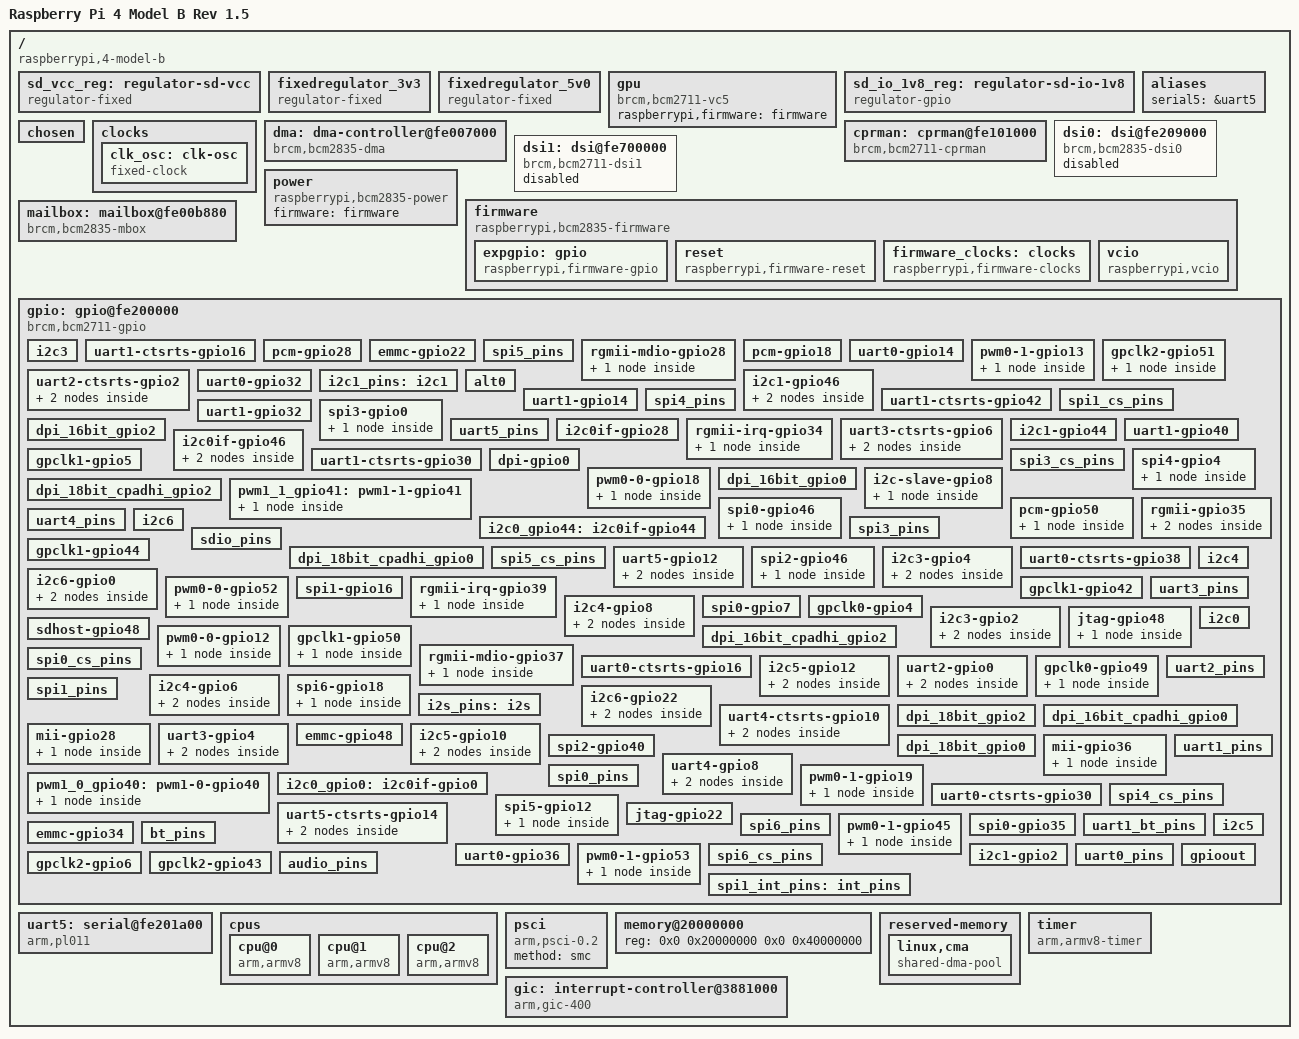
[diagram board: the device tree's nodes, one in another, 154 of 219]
/dts-v1/;
// TODO: Fix 
//
//buildroot login: [   15.462113] platform regulator-sd-vcc: deferred probe pending: platform: supplier firmware:gpio not ready
//[   15.471840] platform firmware:gpio: deferred probe pending: (reason unknown)
//[   15.478986] platform regulator-sd-io-1v8: deferred probe pending: platform: supplier firmware:gpio not ready
//[   15.488930] platform firmware:clocks: deferred probe pending: (reason unknown)
//[   15.496244] platform firmware:reset: deferred probe pending: (reason unknown)
/ {
	#address-cells = <2>;
	#size-cells = <2>;
  interrupt-parent = <&gic>;
	model = "Raspberry Pi 4 Model B Rev 1.5";
	serial-number = "100000000a471c8d";
	compatible = "raspberrypi,4-model-b\0brcm,bcm2711";


	sd_vcc_reg: regulator-sd-vcc {
		regulator-max-microvolt = <0x325aa0>;
		regulator-boot-on;
		gpio = <&expgpio 0x06 0x00>;
		enable-active-high;
		regulator-min-microvolt = <0x325aa0>;
		regulator-name = "vcc-sd";
		compatible = "regulator-fixed";
	};

	fixedregulator_3v3 {
		regulator-max-microvolt = <0x325aa0>;
		regulator-always-on;
		regulator-min-microvolt = <0x325aa0>;
		regulator-name = "3v3";
		compatible = "regulator-fixed";
	};

	fixedregulator_5v0 {
		regulator-max-microvolt = <0x4c4b40>;
		regulator-always-on;
		regulator-min-microvolt = <0x4c4b40>;
		regulator-name = "5v0";
		compatible = "regulator-fixed";
	};

	gpu {
		compatible = "brcm,bcm2711-vc5";
		status = "okay";
		raspberrypi,firmware = <&firmware>;
	};

	sd_io_1v8_reg: regulator-sd-io-1v8 {
		regulator-max-microvolt = <0x325aa0>;
		regulator-boot-on;
		regulator-settling-time-us = <0x1388>;
		regulator-always-on;
		regulator-min-microvolt = <0x1b7740>;
		regulator-name = "vdd-sd-io";
		compatible = "regulator-gpio";
		status = "okay";
		states = <0x1b7740 0x01 0x325aa0 0x00>;
		gpios = <&expgpio 0x04 0x00>;
	};

	aliases {
		serial5 = &uart5;
	//	ethernet0 = &genet;
	};

	chosen {
		stdout-path = "serial5:115200n8";
		bootargs = "coherent_pool=1M earlycon console=serial5,115200 isolcpus=2";
		//bootargs = "coherent_pool=1M earlycon console=serial5,115200 clk_ignore_unused ip=192.168.42.15 carrier_timeout=0 isolcpus=2";
	};


// zone_dma {
// 	dma-ranges = <0x00 0x00 0x00 0x40000000>;
// 	#address-cells = <0x01>;
// 	#size-cells = <0x01>;
// };

	clocks {

	clk_osc:	clk-osc {
			clock-output-names = "osc";
			#clock-cells = <0x00>;
			clock-frequency = <0x337f980>;
			compatible = "fixed-clock";
		};
    };

// soc:	soc {
//		compatible = "simple-bus";
//		#address-cells = <0x01>;
//		#size-cells = <0x01>;
//		ranges = <0x7e000000 0x00 0xfe000000 0x1800000 
//                  0x7c000000 0x00 0xfc000000 0x2000000 
//                  0x40000000 0x00 0xff800000 0x800000>;
//		dma-ranges = <0xc0000000 0x00 0x00 0x40000000 
//                      0x7c000000 0x00 0xfc000000 0x3800000>;
//
//
	 dma:	dma-controller@fe007000 {
			interrupts = <0x00 0x50 0x04 0x00 0x51 0x04 0x00 0x52 0x04 0x00 0x53 0x04 0x00 0x54 0x04 0x00 0x55 0x04 0x00 0x56 0x04 0x00 0x57 0x04 0x00 0x57 0x04 0x00 0x58 0x04 0x00 0x58 0x04>;
			brcm,dma-channel-mask = <0x7f5>;
			compatible = "brcm,bcm2835-dma";
			interrupt-names = "dma0\0dma1\0dma2\0dma3\0dma4\0dma5\0dma6\0dma7\0dma8\0dma9\0dma10";
			reg = <0x0 0xfe007000 0x0 0xb00>;
			#dma-cells = <0x01>;
		};
// };

//
//

	cprman:	cprman@fe101000 {
			clocks = <&clk_osc &dsi0 0x00 &dsi0 0x01 &dsi0 0x02 &dsi1 0x00 &dsi1 0x01 &dsi1 0x02>;
//			clocks = <&clk_osc>;
			#clock-cells = <0x01>;
			compatible = "brcm,bcm2711-cprman";
			firmware = <&firmware>;
			reg = <0x0 0xfe101000 0x0 0x2000>;
		};

	dsi0:	dsi@fe209000 {
			power-domains = <&power 0x11>;
			#address-cells = <0x01>;
			clock-output-names = "dsi0_byte\0dsi0_ddr2\0dsi0_ddr";
			clock-names = "phy\0escape\0pixel";
			interrupts = <0x00 0x64 0x04>;
			clocks = <&cprman 0x22 &cprman 0x2f &cprman 0x31>;
			#size-cells = <0x00>;
			#clock-cells = <0x01>;
			compatible = "brcm,bcm2835-dsi0";
			status = "disabled";
			reg = <0x0 0xfe209000 0x0 0x78>;
		};

	dsi1:	dsi@fe700000 {
			power-domains = <&power 0x12>;
			#address-cells = <0x01>;
			clock-output-names = "dsi1_byte\0dsi1_ddr2\0dsi1_ddr";
			clock-names = "phy\0escape\0pixel";
			interrupts = <0x00 0x6c 0x04>;
			clocks = <&cprman 0x23 &cprman 0x30 &cprman 0x32>;
			#size-cells = <0x00>;
			#clock-cells = <0x01>;
			compatible = "brcm,bcm2711-dsi1";
			status = "disabled";
			reg = <0x0 0xfe700000 0x0 0x8c>;
		};

	power: power {
			compatible = "raspberrypi,bcm2835-power";
			firmware = <&firmware>;
			#power-domain-cells = <0x01>;
		};

	firmware:	firmware {
			dma-ranges;
			#address-cells = <0x01>;
			#size-cells = <0x01>;
			compatible = "raspberrypi,bcm2835-firmware\0simple-mfd";
			mboxes = <&mailbox>;

		expgpio:	gpio {
				gpio-controller;
				gpio-line-names = "BT_ON\0WL_ON\0PWR_LED_OFF\0GLOBAL_RESET\0VDD_SD_IO_SEL\0CAM_GPIO\0SD_PWR_ON\0SD_OC_N";
				compatible = "raspberrypi,firmware-gpio";
				status = "okay";
				#gpio-cells = <0x02>;
			};

		reset:	reset {
				#reset-cells = <0x01>;
				compatible = "raspberrypi,firmware-reset";
			};

		firmware_clocks:	clocks {
				#clock-cells = <0x01>;
				compatible = "raspberrypi,firmware-clocks";
			};

		vcio:	vcio {
				compatible = "raspberrypi,vcio";
			};
		};

	mailbox:	mailbox@fe00b880 {
			interrupts = <0x00 0x21 0x04>;
			#mbox-cells = <0x00>;
			compatible = "brcm,bcm2835-mbox";
			reg = <0x0 0xfe00b880 0x0 0x40>;
		};


	gpio:	gpio@fe200000 {
			compatible = "brcm,bcm2711-gpio";
			reg = <0x0 0xfe200000 0x0 0xb4>;
			interrupts = <0x00 0x71 0x04 0x00 0x72 0x04>;
			gpio-controller;
			#gpio-cells = <0x02>;
			interrupt-controller;
			#interrupt-cells = <0x02>;
			gpio-ranges = <0x07 0x00 0x00 0x3a>;
			gpio-line-names = "ID_SDA\0ID_SCL\0GPIO2\0GPIO3\0GPIO4\0GPIO5\0GPIO6\0GPIO7\0GPIO8\0GPIO9\0GPIO10\0GPIO11\0GPIO12\0GPIO13\0GPIO14\0GPIO15\0GPIO16\0GPIO17\0GPIO18\0GPIO19\0GPIO20\0GPIO21\0GPIO22\0GPIO23\0GPIO24\0GPIO25\0GPIO26\0GPIO27\0RGMII_MDIO\0RGMIO_MDC\0CTS0\0RTS0\0TXD0\0RXD0\0SD1_CLK\0SD1_CMD\0SD1_DATA0\0SD1_DATA1\0SD1_DATA2\0SD1_DATA3\0PWM0_MISO\0PWM1_MOSI\0STATUS_LED_G_CLK\0SPIFLASH_CE_N\0SDA0\0SCL0\0RGMII_RXCLK\0RGMII_RXCTL\0RGMII_RXD0\0RGMII_RXD1\0RGMII_RXD2\0RGMII_RXD3\0RGMII_TXCLK\0RGMII_TXCTL\0RGMII_TXD0\0RGMII_TXD1\0RGMII_TXD2\0RGMII_TXD3";
			phandle = <0x07>;

			i2c3 {
				brcm,pull = <0x02>;
				brcm,function = <0x02>;
				phandle = <0x24>;
				brcm,pins = <0x04 0x05>;
			};

			uart1-ctsrts-gpio16 {
				brcm,function = <0x02>;
				phandle = <0x7f>;
				brcm,pins = <0x10 0x11>;
			};

			pcm-gpio28 {
				brcm,function = <0x06>;
				phandle = <0x72>;
				brcm,pins = <0x1c 0x1d 0x1e 0x1f>;
			};

			emmc-gpio22 {
				brcm,function = <0x07>;
				phandle = <0x65>;
				brcm,pins = <0x16 0x17 0x18 0x19 0x1a 0x1b>;
			};

			spi5_pins {
				brcm,function = <0x07>;
				phandle = <0x20>;
				brcm,pins = <0x0d 0x0e 0x0f>;
			};

			rgmii-mdio-gpio28 {
				phandle = <0xa0>;

				pins-mdio {
					function = "alt5";
					pins = "gpio28\0gpio29";
				};
			};

			pcm-gpio18 {
				brcm,function = <0x04>;
				phandle = <0x71>;
				brcm,pins = <0x12 0x13 0x14 0x15>;
			};

			uart0-gpio14 {
				brcm,function = <0x04>;
				phandle = <0x78>;
				brcm,pins = <0x0e 0x0f>;
			};

			pwm0-1-gpio13 {
				phandle = <0x98>;

				pin-pwm {
					function = "alt0";
					pins = "gpio13";
					bias-disable;
				};
			};

			gpclk2-gpio51 {
				phandle = <0x86>;

				pin-gpclk {
					function = "alt1";
					pins = "gpio51";
					bias-disable;
				};
			};

			uart2-ctsrts-gpio2 {
				phandle = <0xa9>;

				pin-cts {
					function = "alt4";
					pins = "gpio2";
					bias-pull-up;
				};

				pin-rts {
					function = "alt4";
					pins = "gpio3";
					bias-disable;
				};
			};

			uart0-gpio32 {
				brcm,pull = <0x00 0x02>;
				brcm,function = <0x07>;
				phandle = <0x7b>;
				brcm,pins = <0x20 0x21>;
			};

		i2c1_pins:	i2c1 {
				brcm,pull = <0x02>;
				brcm,function = <0x04>;
				phandle = <0x15>;
				brcm,pins = <0x02 0x03>;
			};

			alt0 {
				brcm,function = <0x04>;
				phandle = <0xb9>;
				brcm,pins = <0x04 0x05 0x07 0x08 0x09 0x0a 0x0b>;
			};

			i2c1-gpio46 {
				phandle = <0x88>;

				pin-scl {
					function = "alt1";
					pins = "gpio47";
					bias-disable;
				};

				pin-sda {
					function = "alt1";
					pins = "gpio46";
					bias-pull-up;
				};
			};

			uart1-gpio14 {
				brcm,function = <0x02>;
				phandle = <0x7e>;
				brcm,pins = <0x0e 0x0f>;
			};

			uart1-ctsrts-gpio42 {
				brcm,function = <0x02>;
				phandle = <0x83>;
				brcm,pins = <0x2a 0x2b>;
			};

		spi1_cs_pins:	spi1_cs_pins {
				brcm,function = <0x01>;
				phandle = <0xfe>;
				brcm,pins = <0x12>;
			};

			uart1-gpio32 {
				brcm,function = <0x02>;
				phandle = <0x80>;
				brcm,pins = <0x20 0x21>;
			};

			spi3-gpio0 {
				phandle = <0xa4>;

				pins-spi {
					function = "alt3";
					pins = "gpio0\0gpio1\0gpio2\0gpio3";
				};
			};

			dpi_16bit_gpio2 {
				brcm,function = <0x06>;
				phandle = <0xb5>;
				brcm,pins = <0x02 0x03 0x04 0x05 0x06 0x07 0x08 0x09 0x0a 0x0b 0x0c 0x0d 0x0e 0x0f 0x10 0x11 0x12 0x13>;
			};

		uart5_pins:	uart5_pins {
				brcm,pull = <0x00 0x02>;
				brcm,function = <0x03>;
				phandle = <0x1b>;
				brcm,pins = <0x0c 0x0d>;
			};

			spi4_pins {
				brcm,function = <0x07>;
				phandle = <0x1e>;
				brcm,pins = <0x05 0x06 0x07>;
			};

			i2c0if-gpio28 {
				brcm,function = <0x04>;
				phandle = <0x6d>;
				brcm,pins = <0x1c 0x1d>;
			};

			rgmii-irq-gpio34 {
				phandle = <0x9e>;

				pin-irq {
					function = "alt5";
					pins = "gpio34";
				};
			};

			uart3-ctsrts-gpio6 {
				phandle = <0xab>;

				pin-cts {
					function = "alt4";
					pins = "gpio6";
					bias-pull-up;
				};

				pin-rts {
					function = "alt4";
					pins = "gpio7";
					bias-disable;
				};
			};

			i2c1-gpio44 {
				brcm,function = <0x06>;
				phandle = <0x6f>;
				brcm,pins = <0x2c 0x2d>;
			};

			uart1-gpio40 {
				brcm,function = <0x02>;
				phandle = <0x82>;
				brcm,pins = <0x28 0x29>;
			};

			i2c0if-gpio46 {
				phandle = <0x87>;

				pin-scl {
					function = "alt0";
					pins = "gpio47";
					bias-disable;
				};

				pin-sda {
					function = "alt0";
					pins = "gpio46";
					bias-pull-up;
				};
			};

			gpclk1-gpio5 {
				brcm,function = <0x04>;
				phandle = <0x68>;
				brcm,pins = <0x05>;
			};

			uart1-ctsrts-gpio30 {
				brcm,function = <0x02>;
				phandle = <0x81>;
				brcm,pins = <0x1e 0x1f>;
			};

			dpi-gpio0 {
				brcm,function = <0x06>;
				phandle = <0x64>;
				brcm,pins = <0x00 0x01 0x02 0x03 0x04 0x05 0x06 0x07 0x08 0x09 0x0a 0x0b 0x0c 0x0d 0x0e 0x0f 0x10 0x11 0x12 0x13 0x14 0x15 0x16 0x17 0x18 0x19 0x1a 0x1b>;
			};

		spi3_cs_pins:	spi3_cs_pins {
				brcm,function = <0x01>;
				phandle = <0x1d>;
				brcm,pins = <0x00 0x18>;
			};

			spi4-gpio4 {
				phandle = <0xa5>;

				pins-spi {
					function = "alt3";
					pins = "gpio4\0gpio5\0gpio6\0gpio7";
				};
			};

			pwm0-0-gpio18 {
				phandle = <0x97>;

				pin-pwm {
					function = "alt5";
					pins = "gpio18";
					bias-disable;
				};
			};

			dpi_16bit_gpio0 {
				brcm,function = <0x06>;
				phandle = <0xb4>;
				brcm,pins = <0x00 0x01 0x02 0x03 0x04 0x05 0x06 0x07 0x08 0x09 0x0a 0x0b 0x0c 0x0d 0x0e 0x0f 0x10 0x11 0x12 0x13>;
			};

			dpi_18bit_cpadhi_gpio2 {
				brcm,function = <0x06>;
				phandle = <0xb1>;
				brcm,pins = <0x02 0x03 0x04 0x05 0x06 0x07 0x08 0x09 0x0c 0x0d 0x0e 0x0f 0x10 0x11 0x14 0x15 0x16 0x17 0x18 0x19>;
			};

		pwm1_1_gpio41:	pwm1-1-gpio41 {
				phandle = <0x29>;

				pin-pwm {
					function = "alt0";
					pins = "gpio41";
					bias-disable;
				};
			};

			i2c-slave-gpio8 {
				phandle = <0x91>;

				pins-i2c-slave {
					function = "alt3";
					pins = "gpio8\0gpio9\0gpio10\0gpio11";
				};
			};

			spi0-gpio46 {
				phandle = <0xa2>;

				pins-spi {
					function = "alt2";
					pins = "gpio46\0gpio47\0gpio48\0gpio49";
				};
			};

			pcm-gpio50 {
				phandle = <0x95>;

				pins-pcm {
					function = "alt2";
					pins = "gpio50\0gpio51\0gpio52\0gpio53";
				};
			};

		i2c0_gpio44:	i2c0if-gpio44 {
				brcm,function = <0x05>;
				phandle = <0x34>;
				brcm,pins = <0x2c 0x2d>;
			};

			rgmii-gpio35 {
				phandle = <0x9d>;

				pin-start-stop {
					function = "alt4";
					pins = "gpio35";
				};

				pin-rx-ok {
					function = "alt4";
					pins = "gpio36";
				};
			};

			uart4_pins {
				brcm,pull = <0x00 0x02>;
				brcm,function = <0x03>;
				phandle = <0x1a>;
				brcm,pins = <0x08 0x09>;
			};

		spi3_pins:	spi3_pins {
				brcm,function = <0x07>;
				phandle = <0x1c>;
				brcm,pins = <0x01 0x02 0x03>;
			};

			i2c6 {
				brcm,pull = <0x02>;
				brcm,function = <0x02>;
				phandle = <0x27>;
				brcm,pins = <0x16 0x17>;
			};

			sdio_pins {
				brcm,pull = <0x00 0x02 0x02 0x02 0x02 0x02>;
				brcm,function = <0x07>;
				phandle = <0x31>;
				brcm,pins = <0x22 0x23 0x24 0x25 0x26 0x27>;
			};

			dpi_18bit_cpadhi_gpio0 {
				brcm,pull = <0x00>;
				brcm,function = <0x06>;
				phandle = <0xb0>;
				brcm,pins = <0x00 0x01 0x02 0x03 0x04 0x05 0x06 0x07 0x08 0x09 0x0c 0x0d 0x0e 0x0f 0x10 0x11 0x14 0x15 0x16 0x17 0x18 0x19>;
			};

			gpclk1-gpio44 {
				brcm,function = <0x04>;
				phandle = <0x6a>;
				brcm,pins = <0x2c>;
			};

			spi5_cs_pins {
				brcm,function = <0x01>;
				phandle = <0x21>;
				brcm,pins = <0x0c 0x1a>;
			};

			uart5-gpio12 {
				phandle = <0xae>;

				pin-tx {
					function = "alt4";
					pins = "gpio12";
					bias-disable;
				};

				pin-rx {
					function = "alt4";
					pins = "gpio13";
					bias-pull-up;
				};
			};

			spi2-gpio46 {
				phandle = <0xa3>;

				pins-spi {
					function = "alt5";
					pins = "gpio46\0gpio47\0gpio48\0gpio49\0gpio50";
				};
			};

			i2c3-gpio4 {
				phandle = <0x8a>;

				pin-scl {
					function = "alt5";
					pins = "gpio5";
					bias-disable;
				};

				pin-sda {
					function = "alt5";
					pins = "gpio4";
					bias-pull-up;
				};
			};

			uart0-ctsrts-gpio38 {
				brcm,function = <0x06>;
				phandle = <0x7d>;
				brcm,pins = <0x26 0x27>;
			};

			i2c6-gpio0 {
				phandle = <0x8f>;

				pin-scl {
					function = "alt5";
					pins = "gpio1";
					bias-disable;
				};

				pin-sda {
					function = "alt5";
					pins = "gpio0";
					bias-pull-up;
				};
			};

			pwm0-0-gpio52 {
				phandle = <0x9b>;

				pin-pwm {
					function = "alt1";
					pins = "gpio52";
					bias-disable;
				};
			};

			spi1-gpio16 {
				brcm,function = <0x03>;
				phandle = <0x76>;
				brcm,pins = <0x10 0x11 0x12 0x13 0x14 0x15>;
			};

			rgmii-irq-gpio39 {
				phandle = <0x9f>;

				pin-irq {
					function = "alt4";
					pins = "gpio39";
				};
			};

			i2c4 {
				brcm,pull = <0x02>;
				brcm,function = <0x02>;
				phandle = <0x25>;
				brcm,pins = <0x08 0x09>;
			};

			gpclk1-gpio42 {
				brcm,function = <0x04>;
				phandle = <0x69>;
				brcm,pins = <0x2a>;
			};

			uart3_pins {
				brcm,pull = <0x00 0x02>;
				brcm,function = <0x03>;
				phandle = <0x19>;
				brcm,pins = <0x04 0x05>;
			};

			i2c4-gpio8 {
				phandle = <0x8c>;

				pin-scl {
					function = "alt5";
					pins = "gpio9";
					bias-disable;
				};

				pin-sda {
					function = "alt5";
					pins = "gpio8";
					bias-pull-up;
				};
			};

			spi0-gpio7 {
				brcm,function = <0x04>;
				phandle = <0x74>;
				brcm,pins = <0x07 0x08 0x09 0x0a 0x0b>;
			};

			gpclk0-gpio4 {
				brcm,function = <0x04>;
				phandle = <0x67>;
				brcm,pins = <0x04>;
			};

			i2c3-gpio2 {
				phandle = <0x89>;

				pin-scl {
					function = "alt5";
					pins = "gpio3";
					bias-disable;
				};

				pin-sda {
					function = "alt5";
					pins = "gpio2";
					bias-pull-up;
				};
			};

			jtag-gpio48 {
				phandle = <0x92>;

				pins-jtag {
					function = "alt4";
					pins = "gpio48\0gpio49\0gpio50\0gpio51\0gpio52\0gpio53";
				};
			};

			sdhost-gpio48 {
				brcm,function = <0x04>;
				phandle = <0x73>;
				brcm,pins = <0x30 0x31 0x32 0x33 0x34 0x35>;
			};

			pwm0-0-gpio12 {
				phandle = <0x96>;

				pin-pwm {
					function = "alt0";
					pins = "gpio12";
					bias-disable;
				};
			};

			gpclk1-gpio50 {
				phandle = <0x85>;

				pin-gpclk {
					function = "alt1";
					pins = "gpio50";
					bias-disable;
				};
			};

			dpi_16bit_cpadhi_gpio2 {
				brcm,function = <0x06>;
				phandle = <0xb7>;
				brcm,pins = <0x02 0x03 0x04 0x05 0x06 0x07 0x08 0x0c 0x0d 0x0e 0x0f 0x10 0x11 0x14 0x15 0x16 0x17 0x18>;
			};

			rgmii-mdio-gpio37 {
				phandle = <0xa1>;

				pins-mdio {
					function = "alt4";
					pins = "gpio37\0gpio38";
				};
			};

		spi0_cs_pins:  spi0_cs_pins {
				brcm,function = <0x01>;
				phandle = <0x0f>;
				brcm,pins = <0x08 0x07>;
			};

			uart0-ctsrts-gpio16 {
				brcm,function = <0x07>;
				phandle = <0x79>;
				brcm,pins = <0x10 0x11>;
			};

			i2c5-gpio12 {
				phandle = <0x8e>;

				pin-scl {
					function = "alt5";
					pins = "gpio13";
					bias-disable;
				};

				pin-sda {
					function = "alt5";
					pins = "gpio12";
					bias-pull-up;
				};
			};

			uart2-gpio0 {
				phandle = <0xa8>;

				pin-tx {
					function = "alt4";
					pins = "gpio0";
					bias-disable;
				};

				pin-rx {
					function = "alt4";
					pins = "gpio1";
					bias-pull-up;
				};
			};

			gpclk0-gpio49 {
				phandle = <0x84>;

				pin-gpclk {
					function = "alt1";
					pins = "gpio49";
					bias-disable;
				};
			};

			i2c4-gpio6 {
				phandle = <0x8b>;

				pin-scl {
					function = "alt5";
					pins = "gpio7";
					bias-disable;
				};

				pin-sda {
					function = "alt5";
					pins = "gpio6";
					bias-pull-up;
				};
			};

			spi6-gpio18 {
				phandle = <0xa7>;

				pins-spi {
					function = "alt3";
					pins = "gpio18\0gpio19\0gpio20\0gpio21";
				};
			};

			i2c6-gpio22 {
				phandle = <0x90>;

				pin-scl {
					function = "alt5";
					pins = "gpio23";
					bias-disable;
				};

				pin-sda {
					function = "alt5";
					pins = "gpio22";
					bias-pull-up;
				};
			};

		i2s_pins:	i2s {
				brcm,function = <0x04>;
				phandle = <0x0d>;
				brcm,pins = <0x12 0x13 0x14 0x15>;
			};

			uart4-ctsrts-gpio10 {
				phandle = <0xad>;

				pin-cts {
					function = "alt4";
					pins = "gpio10";
					bias-pull-up;
				};

				pin-rts {
					function = "alt4";
					pins = "gpio11";
					bias-disable;
				};
			};

			dpi_18bit_gpio2 {
				brcm,function = <0x06>;
				phandle = <0xb3>;
				brcm,pins = <0x02 0x03 0x04 0x05 0x06 0x07 0x08 0x09 0x0a 0x0b 0x0c 0x0d 0x0e 0x0f 0x10 0x11 0x12 0x13 0x14 0x15>;
			};

			i2c0 {
				brcm,pull = <0x02>;
				brcm,function = <0x04>;
				phandle = <0xba>;
				brcm,pins = <0x00 0x01>;
			};

			uart2_pins {
				brcm,pull = <0x00 0x02>;
				brcm,function = <0x03>;
				phandle = <0x18>;
				brcm,pins = <0x00 0x01>;
			};

			dpi_16bit_cpadhi_gpio0 {
				brcm,function = <0x06>;
				phandle = <0xb6>;
				brcm,pins = <0x00 0x01 0x02 0x03 0x04 0x05 0x06 0x07 0x08 0x0c 0x0d 0x0e 0x0f 0x10 0x11 0x14 0x15 0x16 0x17 0x18>;
			};

		spi1_pins:	spi1_pins {
				brcm,function = <0x03>;
				phandle = <0xfd>;
				brcm,pins = <0x13 0x14 0x15>;
			};

			mii-gpio28 {
				phandle = <0x93>;

				pins-mii {
					function = "alt4";
					pins = "gpio28\0gpio29\0gpio30\0gpio31";
				};
			};

			uart3-gpio4 {
				phandle = <0xaa>;

				pin-tx {
					function = "alt4";
					pins = "gpio4";
					bias-disable;
				};

				pin-rx {
					function = "alt4";
					pins = "gpio5";
					bias-pull-up;
				};
			};

			emmc-gpio48 {
				brcm,function = <0x07>;
				phandle = <0x13>;
				brcm,pins = <0x30 0x31 0x32 0x33 0x34 0x35>;
			};

			i2c5-gpio10 {
				phandle = <0x8d>;

				pin-scl {
					function = "alt5";
					pins = "gpio11";
					bias-disable;
				};

				pin-sda {
					function = "alt5";
					pins = "gpio10";
					bias-pull-up;
				};
			};

			spi2-gpio40 {
				brcm,function = <0x03>;
				phandle = <0x77>;
				brcm,pins = <0x28 0x29 0x2a 0x2b 0x2c 0x2d>;
			};

			dpi_18bit_gpio0 {
				brcm,function = <0x06>;
				phandle = <0xb2>;
				brcm,pins = <0x00 0x01 0x02 0x03 0x04 0x05 0x06 0x07 0x08 0x09 0x0a 0x0b 0x0c 0x0d 0x0e 0x0f 0x10 0x11 0x12 0x13 0x14 0x15>;
			};

			mii-gpio36 {
				phandle = <0x94>;

				pins-mii {
					function = "alt5";
					pins = "gpio36\0gpio37\0gpio38\0gpio39";
				};
			};

			uart4-gpio8 {
				phandle = <0xac>;

				pin-tx {
					function = "alt4";
					pins = "gpio8";
					bias-disable;
				};

				pin-rx {
					function = "alt4";
					pins = "gpio9";
					bias-pull-up;
				};
			};

			pwm0-1-gpio19 {
				phandle = <0x99>;

				pin-pwm {
					function = "alt5";
					pins = "gpio19";
					bias-disable;
				};
			};

		pwm1_0_gpio40:	pwm1-0-gpio40 {
				phandle = <0x28>;

				pin-pwm {
					function = "alt0";
					pins = "gpio40";
					bias-disable;
				};
			};

		i2c0_gpio0:	i2c0if-gpio0 {
				brcm,function = <0x04>;
				phandle = <0x33>;
				brcm,pins = <0x00 0x01>;
			};

			uart0-ctsrts-gpio30 {
				brcm,pull = <0x02 0x00>;
				brcm,function = <0x07>;
				phandle = <0x7a>;
				brcm,pins = <0x1e 0x1f>;
			};

		uart1_pins:	uart1_pins {
				brcm,pull;
				brcm,function;
				phandle = <0x12>;
				brcm,pins;
			};

		spi0_pins:	spi0_pins {
				brcm,function = <0x04>;
				phandle = <0x0e>;
				brcm,pins = <0x09 0x0a 0x0b>;
			};

			spi4_cs_pins {
				brcm,function = <0x01>;
				phandle = <0x1f>;
				brcm,pins = <0x04 0x19>;
			};

			spi5-gpio12 {
				phandle = <0xa6>;

				pins-spi {
					function = "alt3";
					pins = "gpio12\0gpio13\0gpio14\0gpio15";
				};
			};

			uart5-ctsrts-gpio14 {
				phandle = <0xaf>;

				pin-cts {
					function = "alt4";
					pins = "gpio14";
					bias-pull-up;
				};

				pin-rts {
					function = "alt4";
					pins = "gpio15";
					bias-disable;
				};
			};

			jtag-gpio22 {
				brcm,function = <0x03>;
				phandle = <0x70>;
				brcm,pins = <0x16 0x17 0x18 0x19 0x1a 0x1b>;
			};

			spi6_pins {
				brcm,function = <0x07>;
				phandle = <0x22>;
				brcm,pins = <0x13 0x14 0x15>;
			};

			pwm0-1-gpio45 {
				phandle = <0x9a>;

				pin-pwm {
					function = "alt0";
					pins = "gpio45";
					bias-disable;
				};
			};

			spi0-gpio35 {
				brcm,function = <0x04>;
				phandle = <0x75>;
				brcm,pins = <0x23 0x24 0x25 0x26 0x27>;
			};

			uart1_bt_pins {
				brcm,pull = <0x00 0x02 0x02 0x00>;
				brcm,function = <0x02>;
				phandle = <0xbb>;
				brcm,pins = <0x20 0x21 0x1e 0x1f>;
			};

			emmc-gpio34 {
				brcm,pull = <0x00 0x02 0x02 0x02 0x02 0x02>;
				brcm,function = <0x07>;
				phandle = <0x66>;
				brcm,pins = <0x22 0x23 0x24 0x25 0x26 0x27>;
			};

			bt_pins {
				brcm,pull;
				brcm,function;
				phandle = <0x0a>;
				brcm,pins;
			};

			uart0-gpio36 {
				brcm,function = <0x06>;
				phandle = <0x7c>;
				brcm,pins = <0x24 0x25>;
			};

			i2c5 {
				brcm,pull = <0x02>;
				brcm,function = <0x02>;
				phandle = <0x26>;
				brcm,pins = <0x0c 0x0d>;
			};

			pwm0-1-gpio53 {
				phandle = <0x9c>;

				pin-pwm {
					function = "alt1";
					pins = "gpio53";
					bias-disable;
				};
			};

			spi6_cs_pins {
				brcm,function = <0x01>;
				phandle = <0x23>;
				brcm,pins = <0x12 0x1b>;
			};

			i2c1-gpio2 {
				brcm,function = <0x04>;
				phandle = <0x6e>;
				brcm,pins = <0x02 0x03>;
			};

		uart0_pins:	uart0_pins {
				brcm,pull;
				brcm,function;
				phandle = <0x09>;
				brcm,pins;
			};

			gpclk2-gpio6 {
				brcm,function = <0x04>;
				phandle = <0x6b>;
				brcm,pins = <0x06>;
			};

			gpclk2-gpio43 {
				brcm,pull = <0x00>;
				brcm,function = <0x04>;
				phandle = <0x6c>;
				brcm,pins = <0x2b>;
			};

			audio_pins {
				brcm,pull = <0x00>;
				brcm,function = <0x04>;
				phandle = <0x36>;
				brcm,pins = <0x28 0x29>;
			};

			gpioout {
				brcm,function = <0x01>;
				phandle = <0xb8>;
				brcm,pins = <0x06>;
			};


		spi1_int_pins:	int_pins {
				brcm,pins = <0x18>;
				brcm,function = <0x00>;
				brcm,pull = <0x00>;
				phandle = <0xFA>;
			};

		};


	uart5:	serial@fe201a00 {
			compatible = "arm,pl011\0arm,primecell";
			reg = <0x0 0xfe201a00 0x0 0x200>;
			interrupts = <0x00 0x79 0x04>;
			clocks = <&cprman 0x13 &cprman 0x14>;
			clock-names = "uartclk\0apb_pclk";
			arm,primecell-periphid = <0x241011>;
			status = "okay";
			pinctrl-0 = <&uart5_pins>;
			pinctrl-names = "default";
		};

	cpus {
		#size-cells = <0x0>;
		#address-cells = <0x1>;

		cpu@0 {
			compatible = "arm,armv8";
			device_type = "cpu";
			enable-method = "psci";
			reg = <0x0>;
		};

		cpu@1 {
			compatible = "arm,armv8";
			device_type = "cpu";
			enable-method = "psci";
			reg = <0x1>;
		};

		cpu@2 {
			compatible = "arm,armv8";
			device_type = "cpu";
			enable-method = "psci";
			reg = <0x2>;
		};

	};

	psci {
		compatible = "arm,psci-0.2";
		method = "smc";
	};

	memory@20000000 {
		reg = <0x0 0x20000000 0x0 0x40000000>;
		device_type = "memory";
	};

	reserved-memory {
		#address-cells = <0x02>;
		#size-cells = <0x01>;
		ranges;

		linux,cma {
			compatible = "shared-dma-pool";
			size = <0x4000000>;
			reusable;
			linux,cma-default;
		};
	};

	gic: interrupt-controller@3881000 {
		compatible = "arm,gic-400";
		#interrupt-cells = <3>;
		interrupt-controller;
		reg = <0x0 0xff841000 0x0 0x1000>,
		      <0x0 0xff842000 0x0 0x2000>;
	};

	timer {
		compatible = "arm,armv8-timer";
		interrupts = <0x1 0xd 0xf08 0x1 0xe 0xf08 0x1 0xb 0xf08 0x1 0xa 0xf08>;
	};

//	scb@7c000000 {
//		compatible = "simple-bus";
//		#address-cells = <0x02>;
//		#size-cells = < 0x02 >;
//		dma-ranges = < 0x00 0x00 0x00 0x00 0x04 0x00 >;
//		ranges = < 0x00 0x7c000000 0x00 0xfc000000 0x00 0x3800000 0x00 0x40000000 0x00 0xff800000 0x00 0x800000 0x06 0x00 0x06 0x00 0x00 0x40000000 0x00 0x00 0x00 0x00 0x00 0xfc000000 >;
//
//		genet: ethernet@7d580000 {
//			local-mac-address = [dc a6 32 a3 9c 57];
//			compatible = "brcm,bcm2711-genet-v5", "brcm,genet-v5";
//			reg = < 0x00 0x7d580000 0x00 0x10000 >;
//			#address-cells = <0x1>;
//			#size-cells = <0x1>;
//			interrupts = <0 157 4>,
//						<0 158 4>;
//			status = "okay";
//
//			phy-handle = <&phy1>;
//			phy-mode = "rgmii-rxid";
//
//			genet_mdio: mdio@e14 {
//				compatible = "brcm,genet-mdio-v5";
//				reg = <0xe14 0x8>;
//				reg-names = "mdio";
//				#address-cells = <0x0>;
//				#size-cells = <0x1>;
//
//				phy1: ethernet-phy@1 {
//					reg = <0x01>;
//					led-modes = < 0x00 0x08 >;
//				};
//			};
//		};
//	};

};
